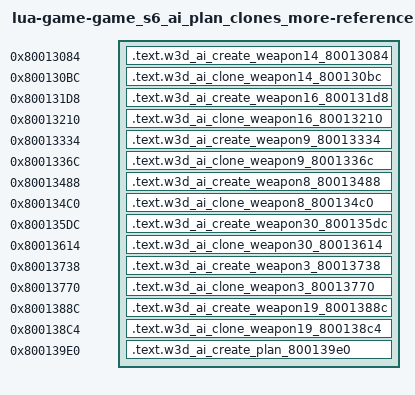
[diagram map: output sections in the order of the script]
/* Generated reference-only placements. All bodies are source-built. */
OUTPUT_FORMAT("elf32-powerpc")
OUTPUT_ARCH(powerpc)
ENTRY(w3d_ai_create_weapon14_80013084)
_SDA_BASE_ = 0x804b2540;
_SDA2_BASE_ = 0x804c2540;
w3d_auto_8001523c = 0x8001523c;
w3d_f32_8036a4bc = 0x8036a4bc;
w3d_f32_8036a4c0 = 0x8036a4c0;
w3d_f32_8036a4c8 = 0x8036a4c8;
w3d_f32_8036a4cc = 0x8036a4cc;
w3d_f32_8036a4d0 = 0x8036a4d0;
w3d_f32_8036a4d8 = 0x8036a4d8;
w3d_f32_8036a4dc = 0x8036a4dc;
w3d_fn_80013a18 = 0x80013a18;
w3d_path_cost_construct = 0x80006360;
w3d_vtable_8040d180 = 0x8040d180;
w3d_vtable_8040d1b8 = 0x8040d1b8;
w3d_vtable_8040d228 = 0x8040d228;
w3d_vtable_8040d268 = 0x8040d268;
w3d_vtable_8040d2a8 = 0x8040d2a8;
w3d_vtable_8040d328 = 0x8040d328;
w3d_vtable_8040d368 = 0x8040d368;
w3d_vtable_8040d7b8 = 0x8040d7b8;
SECTIONS {
  .text.w3d_ai_create_weapon14_80013084 0x80013084 : { *(.text.w3d_ai_create_weapon14_80013084) }
  .text.w3d_ai_clone_weapon14_800130bc 0x800130bc : { *(.text.w3d_ai_clone_weapon14_800130bc) }
  .text.w3d_ai_create_weapon16_800131d8 0x800131d8 : { *(.text.w3d_ai_create_weapon16_800131d8) }
  .text.w3d_ai_clone_weapon16_80013210 0x80013210 : { *(.text.w3d_ai_clone_weapon16_80013210) }
  .text.w3d_ai_create_weapon9_80013334 0x80013334 : { *(.text.w3d_ai_create_weapon9_80013334) }
  .text.w3d_ai_clone_weapon9_8001336c 0x8001336c : { *(.text.w3d_ai_clone_weapon9_8001336c) }
  .text.w3d_ai_create_weapon8_80013488 0x80013488 : { *(.text.w3d_ai_create_weapon8_80013488) }
  .text.w3d_ai_clone_weapon8_800134c0 0x800134c0 : { *(.text.w3d_ai_clone_weapon8_800134c0) }
  .text.w3d_ai_create_weapon30_800135dc 0x800135dc : { *(.text.w3d_ai_create_weapon30_800135dc) }
  .text.w3d_ai_clone_weapon30_80013614 0x80013614 : { *(.text.w3d_ai_clone_weapon30_80013614) }
  .text.w3d_ai_create_weapon3_80013738 0x80013738 : { *(.text.w3d_ai_create_weapon3_80013738) }
  .text.w3d_ai_clone_weapon3_80013770 0x80013770 : { *(.text.w3d_ai_clone_weapon3_80013770) }
  .text.w3d_ai_create_weapon19_8001388c 0x8001388c : { *(.text.w3d_ai_create_weapon19_8001388c) }
  .text.w3d_ai_clone_weapon19_800138c4 0x800138c4 : { *(.text.w3d_ai_clone_weapon19_800138c4) }
  .text.w3d_ai_create_plan_800139e0 0x800139e0 : { *(.text.w3d_ai_create_plan_800139e0) }
  /DISCARD/ : { *(.text*) *(.rodata*) *(.data*) *(.bss*) *(.sdata*) *(.sbss*) *(.comment) }
}
